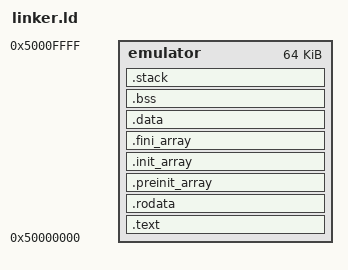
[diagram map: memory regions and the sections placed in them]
INCLUDE generated/output_format.ld
ENTRY(_start)

__DYNAMIC = 0;

MEMORY {
	emulator : ORIGIN = 0x50000000, LENGTH = 0x00010000
}

SECTIONS
{
	.text :
	{
		_ftext = .;
		*(.text .stub .text.* .gnu.linkonce.t.*)
		_etext = .;
	} > emulator

	.rodata :
	{
		. = ALIGN(4);
		_frodata = .;
		*(.rodata .rodata.* .gnu.linkonce.r.*)
		*(.rodata1)
		_erodata = .;
	} > emulator

	/* Modern LiteX's libbase/startup.c references these; the 2020 script
	   this derives from predates that. */
	.preinit_array :
	{
		. = ALIGN(8);
		PROVIDE_HIDDEN (__preinit_array_start = .);
		KEEP(*(SORT(.preinit_array.*)))
		KEEP(*(.preinit_array))
		PROVIDE_HIDDEN (__preinit_array_end = .);
	} > emulator

	.init_array :
	{
		. = ALIGN(8);
		PROVIDE_HIDDEN (__init_array_start = .);
		KEEP(*(SORT(.init_array.*)))
		KEEP(*(.init_array))
		KEEP(*(SORT(.ctors.*)))
		KEEP(*(.ctors))
		PROVIDE_HIDDEN (__init_array_end = .);
	} > emulator

	.fini_array :
	{
		. = ALIGN(8);
		PROVIDE_HIDDEN (__fini_array_start = .);
		KEEP(*(SORT(.fini_array.*)))
		KEEP(*(.fini_array))
		KEEP(*(SORT(.dtors.*)))
		KEEP(*(.dtors))
		PROVIDE_HIDDEN (__fini_array_end = .);
	} > emulator

	.data :
	{
		. = ALIGN(4);
		_fdata = .;
		*(.data .data.* .gnu.linkonce.d.*)
		*(.data1)
		_gp = ALIGN(16);
		*(.sdata .sdata.* .gnu.linkonce.s.*)
		_edata = .;
	} > emulator

	.bss :
	{
		. = ALIGN(4);
		_fbss = .;
		*(.dynsbss)
		*(.sbss .sbss.* .gnu.linkonce.sb.*)
		*(.scommon)
		*(.dynbss)
		*(.bss .bss.* .gnu.linkonce.b.*)
		*(COMMON)
		. = ALIGN(4);
		_ebss = .;
		_end = .;
	} > emulator

	__stack_size = DEFINED(__stack_size) ? __stack_size : 2K;
	.stack :
	{
		PROVIDE( _heap_end = . );
		. = __stack_size;
		PROVIDE( _sp = . );
	} > emulator
}

PROVIDE(_fstack = ORIGIN(emulator) + LENGTH(emulator) - 4);

PROVIDE(_fdata_rom = LOADADDR(.data));
PROVIDE(_edata_rom = LOADADDR(.data) + SIZEOF(.data));
